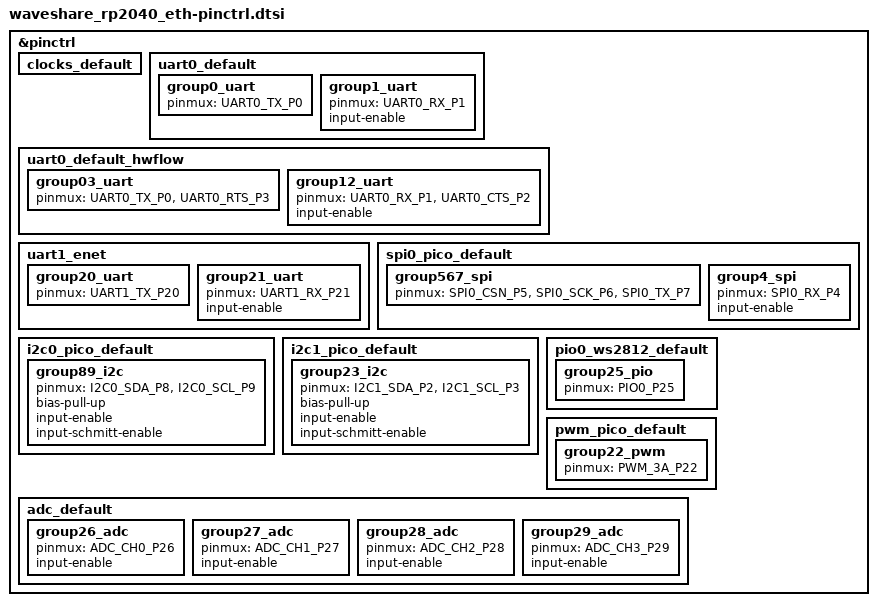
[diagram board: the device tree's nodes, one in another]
/*
 * SPDX-FileCopyrightText: Copyright (c) 2023-2026 TiaC Systems
 * SPDX-License-Identifier: Apache-2.0
 */

#include <zephyr/dt-bindings/pinctrl/rpi-pico-rp2040-pinctrl.h>

&pinctrl {
	clocks_default: clocks_default {
		/* no external clocks */
	};

	uart0_default: uart0_default {
		group0_uart {
			pinmux = <UART0_TX_P0>;		/* GP0: UART0_TX */
		};
		group1_uart {
			pinmux = <UART0_RX_P1>;		/* GP1: UART0_RX */
			input-enable;
		};
	};

	uart0_default_hwflow: uart0_default_hwflow {
		group03_uart {
			pinmux = <UART0_TX_P0>,		/* GP0: UART0_TX */
				 <UART0_RTS_P3>;	/* GP3: UART0_RTS */
		};
		group12_uart {
			pinmux = <UART0_RX_P1>,		/* GP1: UART0_RX */
				 <UART0_CTS_P2>;	/* GP2: UART0_CTS */
			input-enable;
		};
	};

	uart1_enet: uart1_enet {
		group20_uart {
			pinmux = <UART1_TX_P20>;	/* GP20: UART1_TX */
		};
		group21_uart {
			pinmux = <UART1_RX_P21>;	/* GP21: UART1_RX */
			input-enable;
		};
	};

	spi0_pico_default: spi0_pico_default {
		group567_spi {
			pinmux = <SPI0_CSN_P5>,		/* GP5: SPI0_CSN */
				 <SPI0_SCK_P6>,		/* GP6: SPI0_SCK */
				 <SPI0_TX_P7>;		/* GP7: SPI0_TX */
		};
		group4_spi {
			pinmux = <SPI0_RX_P4>;		/* GP4: SPI0_RX */
			input-enable;
		};
	};

	i2c0_pico_default: i2c0_pico_default {
		group89_i2c {
			pinmux = <I2C0_SDA_P8>,		/* GP8: I2C0_SDA */
				 <I2C0_SCL_P9>;		/* GP9: I2C0_SCL */
			bias-pull-up;
			input-enable;
			input-schmitt-enable;
		};
	};

	i2c1_pico_default: i2c1_pico_default {
		group23_i2c {
			pinmux = <I2C1_SDA_P2>,		/* GP2: I2C1_SDA */
				 <I2C1_SCL_P3>;		/* GP3: I2C1_SCL */
			bias-pull-up;
			input-enable;
			input-schmitt-enable;
		};
	};

	pio0_ws2812_default: pio0_ws2812_default {
		group25_pio {
			pinmux = <PIO0_P25>;		/* GP25: PIO0 */
		};
	};

	pwm_pico_default: pwm_pico_default {
		group22_pwm {
			pinmux = <PWM_3A_P22>;		/* GP22: PWM3CHA (6) */
		};
	};

	adc_default: adc_default {
		group26_adc {
			pinmux = <ADC_CH0_P26>;		/* GP26: ADC_CH0 */
			input-enable;
		};
		group27_adc {
			pinmux = <ADC_CH1_P27>;		/* GP27: ADC_CH1 */
			input-enable;
		};
		group28_adc {
			pinmux = <ADC_CH2_P28>;		/* GP28: ADC_CH2 */
			input-enable;
		};
		group29_adc {
			pinmux = <ADC_CH3_P29>;		/* GP29: ADC_CH3 */
			input-enable;
		};
	};
};
